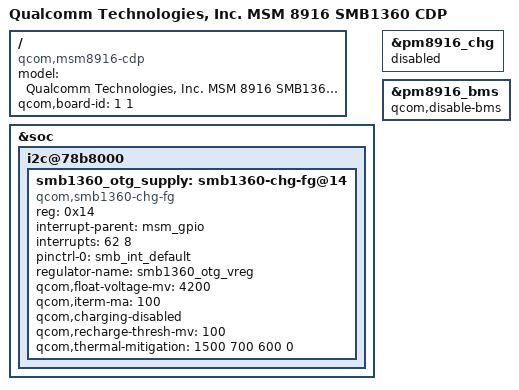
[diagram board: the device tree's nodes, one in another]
/* Copyright (c) 2014, The Linux Foundation. All rights reserved.
*
* This program is free software; you can redistribute it and/or modify
* it under the terms of the GNU General Public License version 2 and
* only version 2 as published by the Free Software Foundation.
*
* This program is distributed in the hope that it will be useful,
* but WITHOUT ANY WARRANTY; without even the implied warranty of
* MERCHANTABILITY or FITNESS FOR A PARTICULAR PURPOSE.  See the
* GNU General Public License for more details.
*/

/dts-v1/;

#include "msm8916-cdp.dtsi"
#include "msm8916-memory.dtsi"

/ {
	model = "Qualcomm Technologies, Inc. MSM 8916 SMB1360 CDP";
	compatible = "qcom,msm8916-cdp", "qcom,msm8916", "qcom,cdp";
	qcom,board-id = <1 1>;
};

&soc {
	i2c@78b8000 {
		smb1360_otg_supply: smb1360-chg-fg@14 {
			compatible = "qcom,smb1360-chg-fg";
			reg = <0x14>;
			interrupt-parent = <&msm_gpio>;
			interrupts = <62 8>;
			pinctrl-names = "default";
			pinctrl-0 = <&smb_int_default>;
			regulator-name = "smb1360_otg_vreg";

			qcom,float-voltage-mv = <4200>;
			qcom,iterm-ma = <100>;
			qcom,charging-disabled;
			qcom,recharge-thresh-mv = <100>;
			qcom,thermal-mitigation = <1500 700 600 0>;
		};
	};
};

&pm8916_chg {
	status = "disabled";
};

&pm8916_bms {
	status = "ok";
	qcom,disable-bms;
};
